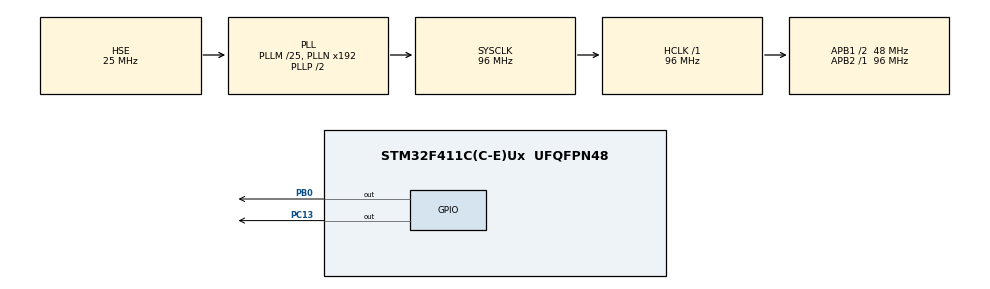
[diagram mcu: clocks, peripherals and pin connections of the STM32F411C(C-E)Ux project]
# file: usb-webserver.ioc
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Mcu.Family=STM32F4
Mcu.Name=STM32F411C(C-E)Ux
Mcu.Package=UFQFPN48
NVIC.PriorityGroup=NVIC_PRIORITYGROUP_4
PB0.Signal=GPIO_Output
PC13-ANTI_TAMP.Signal=GPIO_Output
PH0\ -\ OSC_IN.Mode=HSE-External-Oscillator
PH0\ -\ OSC_IN.Signal=RCC_OSC_IN
PH1\ -\ OSC_OUT.Mode=HSE-External-Oscillator
PH1\ -\ OSC_OUT.Signal=RCC_OSC_OUT
ProjectManager.HeapSize=0x200
ProjectManager.StackSize=0x400
ProjectManager.TargetToolchain=CMake
RCC.48MHZClocksFreq_Value=48000000
RCC.AHBFreq_Value=96000000
RCC.APB1CLKDivider=RCC_HCLK_DIV2
RCC.APB1Freq_Value=48000000
RCC.APB1TimFreq_Value=96000000
RCC.APB2Freq_Value=96000000
RCC.APB2TimFreq_Value=96000000
RCC.CortexFreq_Value=96000000
RCC.HCLKFreq_Value=96000000
RCC.HSE_VALUE=25000000
RCC.HSI_VALUE=16000000
RCC.LSE_VALUE=32768
RCC.PLLM=25
RCC.PLLSourceVirtual=RCC_PLLSOURCE_HSE
RCC.SYSCLKFreq_VALUE=96000000
RCC.SYSCLKSource=RCC_SYSCLKSOURCE_PLLCLK
RCC.VCOOutputFreq_Value=192000000
board=custom

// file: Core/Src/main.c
/* USER CODE BEGIN Header */
/**
  ******************************************************************************
  * @file           : main.c
  * @brief          : Main program body
  ******************************************************************************
  * @attention
  *
  * Copyright (c) 2026 STMicroelectronics.
  * All rights reserved.
  *
  * This software is licensed under terms that can be found in the LICENSE file
  * in the root directory of this software component.
  * If no LICENSE file comes with this software, it is provided AS-IS.
  *
  ******************************************************************************
  */
/* USER CODE END Header */
#include "main.h"
#include "gpio.h"

/* USER CODE BEGIN Includes */
#include "tusb.h"
#include "lwip/timeouts.h"
#include "hardware.h"
/* USER CODE END Includes */

void SystemClock_Config(void);
/* USER CODE BEGIN PFP */
void usb_network_init(void);
void usb_network_services_init(void);
/* USER CODE END PFP */

/* USER CODE BEGIN 0 */
static void MX_TinyUSB_Init(void)
{
  GPIO_InitTypeDef GPIO_InitStruct = {0};

  // Configure USB D+ and D- pins: PA11 and PA12
  __HAL_RCC_GPIOA_CLK_ENABLE();

  GPIO_InitStruct.Pin = GPIO_PIN_11 | GPIO_PIN_12;
  GPIO_InitStruct.Mode = GPIO_MODE_AF_PP;
  GPIO_InitStruct.Pull = GPIO_NOPULL;
  GPIO_InitStruct.Speed = GPIO_SPEED_FREQ_HIGH;
  GPIO_InitStruct.Alternate = GPIO_AF10_OTG_FS;
  HAL_GPIO_Init(GPIOA, &GPIO_InitStruct);

  // Configure USB VBUS pin (PA9)
  GPIO_InitStruct.Pin = GPIO_PIN_9;
  GPIO_InitStruct.Mode = GPIO_MODE_INPUT;
  GPIO_InitStruct.Pull = GPIO_NOPULL;
  HAL_GPIO_Init(GPIOA, &GPIO_InitStruct);

  // Configure USB ID pin (PA10)
  GPIO_InitStruct.Pin = GPIO_PIN_10;
  GPIO_InitStruct.Mode = GPIO_MODE_AF_OD;
  GPIO_InitStruct.Pull = GPIO_PULLUP;
  GPIO_InitStruct.Speed = GPIO_SPEED_FREQ_HIGH;
  GPIO_InitStruct.Alternate = GPIO_AF10_OTG_FS;
  HAL_GPIO_Init(GPIOA, &GPIO_InitStruct);

  // Enable USB OTG FS peripheral clock
  __HAL_RCC_USB_OTG_FS_CLK_ENABLE();
  HAL_NVIC_SetPriority(OTG_FS_IRQn, 5, 0);
  HAL_NVIC_EnableIRQ(OTG_FS_IRQn);

  // Configure TinyUSB DWC2 without hardware VBUS sensing
  tud_configure_dwc2_t dwc2_cfg = CFG_TUD_CONFIGURE_DWC2_DEFAULT;
  dwc2_cfg.vbus_sensing = false;

  tud_configure(0, TUD_CFGID_DWC2, &dwc2_cfg);

  // Initialize TinyUSB device stack
  tusb_rhport_init_t dev_init = {
    .role = TUSB_ROLE_DEVICE,
    .speed = TUSB_SPEED_AUTO
};

  tusb_init(0, &dev_init);
}

static void LED_Status_Task(void)
{
  static uint32_t last_blink = 0;
  static bool led_state = false;

  uint32_t interval;

  if (tud_suspended()) {
    interval = 2500;
  }
  else if (tud_mounted()) {
    interval = 1000;
  }
  else {
    interval = 250;
  }

  if (HAL_GetTick() - last_blink >= interval) {
    last_blink = HAL_GetTick();
    led_state = !led_state;

    HAL_GPIO_WritePin(
        GPIOC,
        GPIO_PIN_13,
        led_state ? GPIO_PIN_RESET : GPIO_PIN_SET
    );
  }
}

// TinyUSB uses this function for its millisecond time source.
// CubeMX already maintains the HAL tick through SysTick.
uint32_t tusb_time_millis_api(void)
{
  return HAL_GetTick();
}
/* USER CODE END 0 */

int main(void)
{

  /* MCU Configuration--------------------------------------------------------*/

  /* Reset of all peripherals, Initializes the Flash interface and the Systick. */
  HAL_Init();

  /* Configure the system clock */
  SystemClock_Config();

  /* Initialize all configured peripherals */
  MX_GPIO_Init();
  /* USER CODE BEGIN 2 */
  MX_TinyUSB_Init();

  usb_network_init();
  usb_network_services_init();

  Hardware_Init();
  /* USER CODE END 2 */

  /* Infinite loop */
  while (1)
  {

    /* USER CODE BEGIN 3 */
    tud_task();
    sys_check_timeouts();
    LED_Status_Task();
    Hardware_Task();
  }
  /* USER CODE END 3 */
}

void SystemClock_Config(void)
{
  RCC_OscInitTypeDef RCC_OscInitStruct = {0};
  RCC_ClkInitTypeDef RCC_ClkInitStruct = {0};

  /** Configure the main internal regulator output voltage
  */
  __HAL_RCC_PWR_CLK_ENABLE();
  __HAL_PWR_VOLTAGESCALING_CONFIG(PWR_REGULATOR_VOLTAGE_SCALE1);

  /** Initializes the RCC Oscillators according to the specified parameters
  * in the RCC_OscInitTypeDef structure.
  */
  RCC_OscInitStruct.OscillatorType = RCC_OSCILLATORTYPE_HSE;
  RCC_OscInitStruct.HSEState = RCC_HSE_ON;
  RCC_OscInitStruct.PLL.PLLState = RCC_PLL_ON;
  RCC_OscInitStruct.PLL.PLLSource = RCC_PLLSOURCE_HSE;
  RCC_OscInitStruct.PLL.PLLM = 25;
  RCC_OscInitStruct.PLL.PLLN = 192;
  RCC_OscInitStruct.PLL.PLLP = RCC_PLLP_DIV2;
  RCC_OscInitStruct.PLL.PLLQ = 4;
  if (HAL_RCC_OscConfig(&RCC_OscInitStruct) != HAL_OK)
  {
    Error_Handler();
  }

  /** Initializes the CPU, AHB and APB buses clocks
  */
  RCC_ClkInitStruct.ClockType = RCC_CLOCKTYPE_HCLK|RCC_CLOCKTYPE_SYSCLK
                              |RCC_CLOCKTYPE_PCLK1|RCC_CLOCKTYPE_PCLK2;
  RCC_ClkInitStruct.SYSCLKSource = RCC_SYSCLKSOURCE_PLLCLK;
  RCC_ClkInitStruct.AHBCLKDivider = RCC_SYSCLK_DIV1;
  RCC_ClkInitStruct.APB1CLKDivider = RCC_HCLK_DIV2;
  RCC_ClkInitStruct.APB2CLKDivider = RCC_HCLK_DIV1;

  if (HAL_RCC_ClockConfig(&RCC_ClkInitStruct, FLASH_LATENCY_3) != HAL_OK)
  {
    Error_Handler();
  }
}

void Error_Handler(void)
{
  __disable_irq();
  while (1)
  {
  }
}
